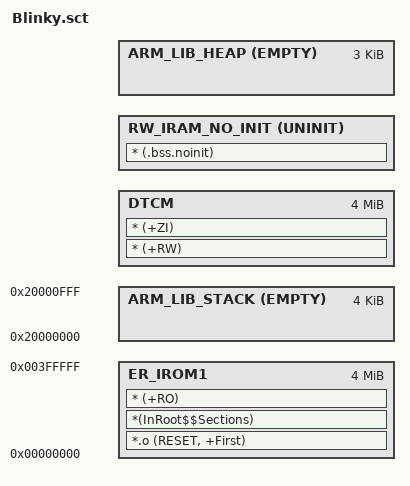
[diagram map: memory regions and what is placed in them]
; *************************************************************
; *** Scatter-Loading Description File generated by uVision ***
; *************************************************************

LR_IROM1 0x00000000 0x00400000  {    ; load region size_region
    ER_IROM1 0x00000000 0x00400000  {  ; load address = execution address
    *.o (RESET, +First)
    *(InRoot$$Sections)
    * (+RO)
    }
    
    ARM_LIB_STACK 0x20000000 ALIGN 8  EMPTY 0x00001000 {
    }
    DTCM +0 0x00400000  {  ; RW data
        * (+RW)
        * (+ZI)
    }
    RW_IRAM_NO_INIT +0 UNINIT  {
      * (.bss.noinit)
    }
    
    ARM_LIB_HEAP  +0 ALIGN 8 EMPTY 0x0000C00  {
    }
    
}

